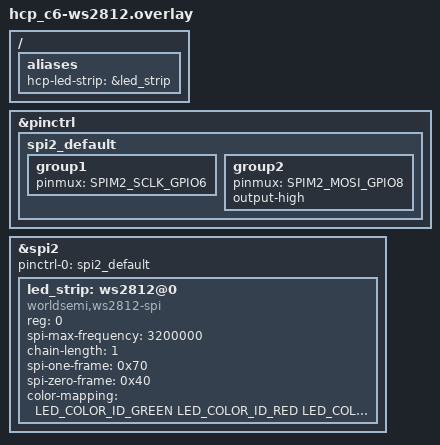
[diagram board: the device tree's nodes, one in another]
/*
 * ESP32-C6 specific: optional WS2812 binding for the hcp_c6 board.
 * Applied on demand via: build.sh hcp_c6/... --led
 *   (which passes -DEXTRA_DTC_OVERLAY_FILE=boards/helios/hcp_c6/hcp_c6-ws2812.overlay)
 *
 * Binds Zephyr's in-tree worldsemi,ws2812-spi driver: strip data = SPI2 MOSI
 * routed to GPIO8; SPI also needs a clock line (SCLK -> GPIO6, NOT wired to the
 * strip). Chip-specific (pinctrl macros / SPI controller), so it lives under the
 * board dir, not in the arch-neutral lib/led.
 *
 * c3/c5 need their own equivalent overlay (different pinctrl header + SPI/pins).
 */

#include <zephyr/dt-bindings/led/led.h>
#include <zephyr/dt-bindings/pinctrl/esp32c6-pinctrl.h>

/ {
	aliases {
		hcp-led-strip = &led_strip;
	};
};

&pinctrl {
	spi2_default: spi2_default {
		group1 {
			pinmux = <SPIM2_SCLK_GPIO6>;   /* SPI clock, not wired to the strip */
		};
		group2 {
			pinmux = <SPIM2_MOSI_GPIO8>;   /* strip data line */
			output-high;
		};
	};
};

&spi2 {
	status = "okay";
	#address-cells = <1>;
	#size-cells = <0>;
	pinctrl-0 = <&spi2_default>;
	pinctrl-names = "default";

	led_strip: ws2812@0 {
		compatible = "worldsemi,ws2812-spi";
		reg = <0>;
		spi-max-frequency = <3200000>;
		chain-length = <1>;

		spi-one-frame = <0x70>;
		spi-zero-frame = <0x40>;

		color-mapping = <LED_COLOR_ID_GREEN
				 LED_COLOR_ID_RED
				 LED_COLOR_ID_BLUE>;
	};
};
